# STM32H743 register map
File version: 2.4
CPU: CM7 r0p1, little endian, MPU, FPU, 4 interrupt priority bits
Registers are 32-bit, read-write, reset 0x0 unless marked. A register's access mark holds for its fields unless they carry their own. Offsets are from the block's base; [hi:lo] are bit positions; {n}, {i} and the like mark numbered series.

## DCMI — 数字摄像头接口
Base 0x48020000
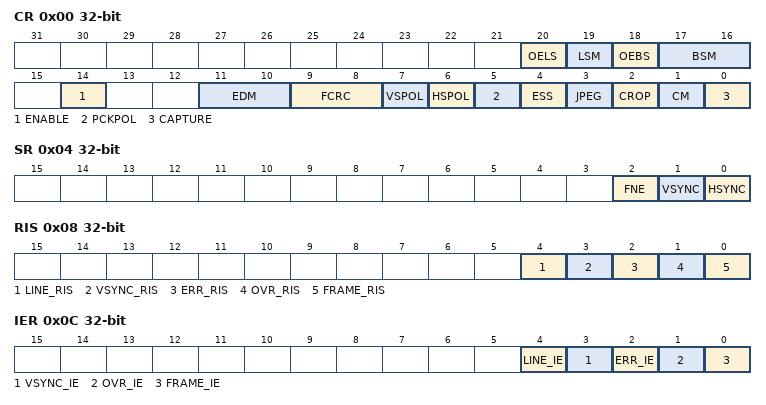
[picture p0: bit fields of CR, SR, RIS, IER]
0x00 CR — 控制寄存器 1
  [20] OELS — 奇/偶行选择（行选择起始）
  [19] LSM — 行选择模式
  [18] OEBS — 奇/偶字节选择（字节选择起始）
  [17:16] BSM — 字节选择模式
  [14] ENABLE — DCMI 使能
  [11:10] EDM — 扩展数据模式
  [9:8] FCRC — 帧捕获速率控制
  [7] VSPOL — 垂直同步极性
  [6] HSPOL — 水平同步极性
  [5] PCKPOL — 像素时钟极性
  [4] ESS — 内嵌同步选择
  [3] JPEG — JPEG 格式
  [2] CROP — 裁剪功能
  [1] CM — 捕获模式
  [0] CAPTURE — 捕获使能
0x04 SR ro — 状态寄存器
  [2] FNE — FIFO 非空
  [1] VSYNC
  [0] HSYNC
0x08 RIS ro — 原始中断状态寄存器
  [4] LINE_RIS — 行原始中断状态
  [3] VSYNC_RIS — VSYNC 原始中断状态
  [2] ERR_RIS — 同步错误原始中断状态
  [1] OVR_RIS — 溢出原始中断状态
  [0] FRAME_RIS — 捕获完成原始中断状态
0x0C IER — 中断使能寄存器
  [4] LINE_IE — 行中断使能
  [3] VSYNC_IE — VSYNC 中断使能
  [2] ERR_IE — 同步错误中断使能
  [1] OVR_IE — 溢出中断使能
  [0] FRAME_IE — 捕获完成中断使能
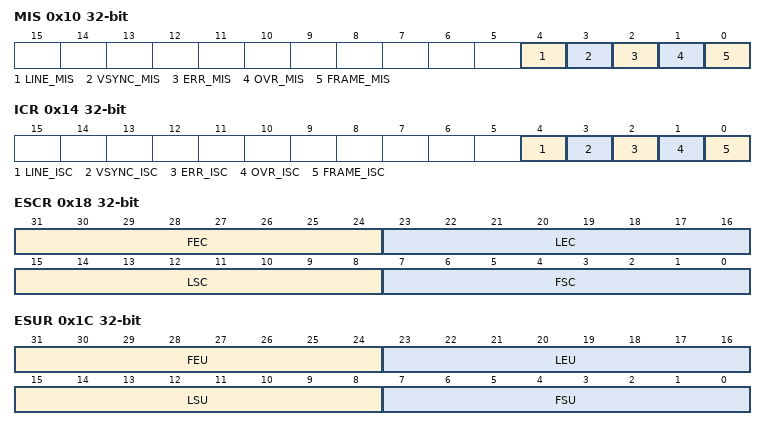
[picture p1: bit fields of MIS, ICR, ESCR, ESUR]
0x10 MIS ro — 已屏蔽中断状态寄存器
  [4] LINE_MIS — 行已屏蔽中断状态
  [3] VSYNC_MIS — VSYNC 已屏蔽中断状态
  [2] ERR_MIS — 同步错误已屏蔽中断状态
  [1] OVR_MIS — 溢出已屏蔽中断状态
  [0] FRAME_MIS — 捕获完成已屏蔽中断状态
0x14 ICR wo — 中断清除寄存器
  [4] LINE_ISC — 行中断状态清除
  [3] VSYNC_ISC — 垂直同步中断状态清除
  [2] ERR_ISC — 同步错误中断状态清除
  [1] OVR_ISC — 溢出中断状态清除
  [0] FRAME_ISC — 捕获完成中断状态清除
0x18 ESCR — 内嵌同步码寄存器
  [31:24] FEC — 帧结束分隔码
  [23:16] LEC — 行结束分隔码
  [15:8] LSC — 行起始分隔码
  [7:0] FSC — 帧起始分隔码
0x1C ESUR — 内嵌同步非屏蔽寄存器
  [31:24] FEU — 帧结束分隔符非屏蔽
  [23:16] LEU — 行结束分隔符非屏蔽
  [15:8] LSU — 行起始分隔符非屏蔽
  [7:0] FSU — 帧起始分隔符非屏蔽
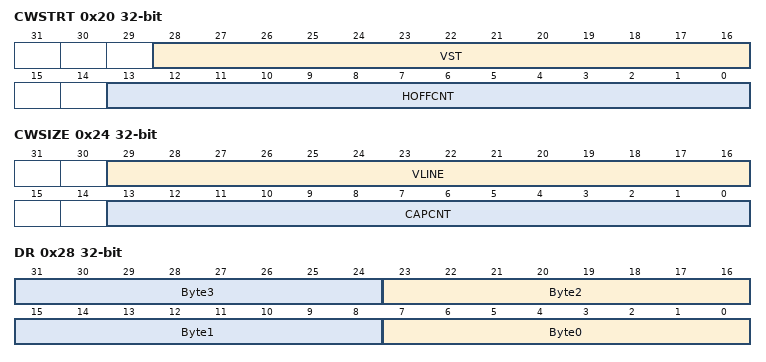
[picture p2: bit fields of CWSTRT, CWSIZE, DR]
0x20 CWSTRT — 裁剪窗口起始
  [28:16] VST — 垂直起始行计数
  [13:0] HOFFCNT — 水平偏移计数
0x24 CWSIZE — 裁剪窗口大小
  [29:16] VLINE — 垂直行数
  [13:0] CAPCNT — 捕获计数
0x28 DR ro — 数据寄存器
  [8n+7:8n] Byte{n} (n=0..3) — 数据字节 {n}

## OTG1_HS_PWRCLK — USB 1 OTG 高速接口
Base 0x40040E00
Same registers: OTG2_HS_PWRCLK 0x40080E00
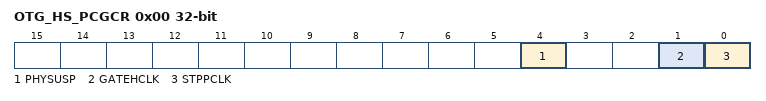
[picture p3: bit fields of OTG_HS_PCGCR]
0x00 OTG_HS_PCGCR — 功耗与时钟门控寄存器
  [4] PHYSUSP — PHY 已挂起
  [1] GATEHCLK — 门控 HCLK
  [0] STPPCLK — 停止 PHY 时钟

## Ethernet_DMA — 以太网：DMA 控制器
Base 0x40029000
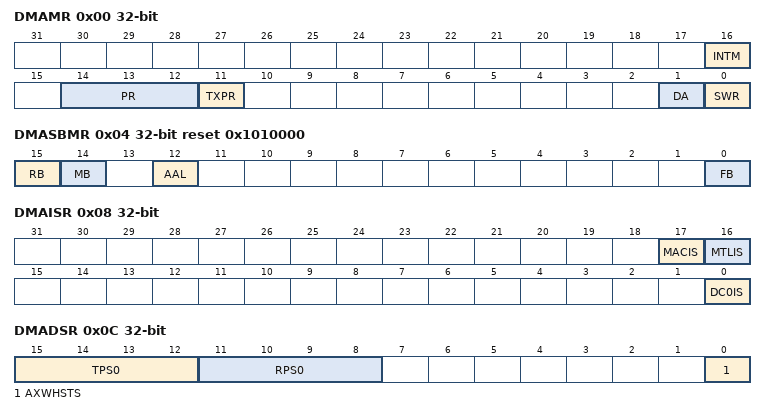
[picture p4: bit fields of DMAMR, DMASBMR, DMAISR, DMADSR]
0x00 DMAMR access per field — DMA 模式寄存器
  [16] INTM rw — 中断模式
  [14:12] PR ro — 优先级比例
  [11] TXPR ro — 发送优先级
  [1] DA ro — DMA 发送或接收仲裁方案
  [0] SWR rw — 软件复位
0x04 DMASBMR access per field reset 0x1010000 — 系统总线模式寄存器
  [15] RB ro — 重建 INCRx 突发
  [14] MB ro — 混合突发
  [12] AAL rw — 地址对齐节拍
  [0] FB rw — 固定突发长度
0x08 DMAISR ro — 中断状态寄存器
  [17] MACIS — MAC 中断状态
  [16] MTLIS — MTL 中断状态
  [0] DC0IS — DMA 通道中断状态
0x0C DMADSR ro — 调试状态寄存器
  [15:12] TPS0 — DMA 通道发送处理状态
  [11:8] RPS0 — DMA 通道接收处理状态
  [0] AXWHSTS — AHB 主写通道
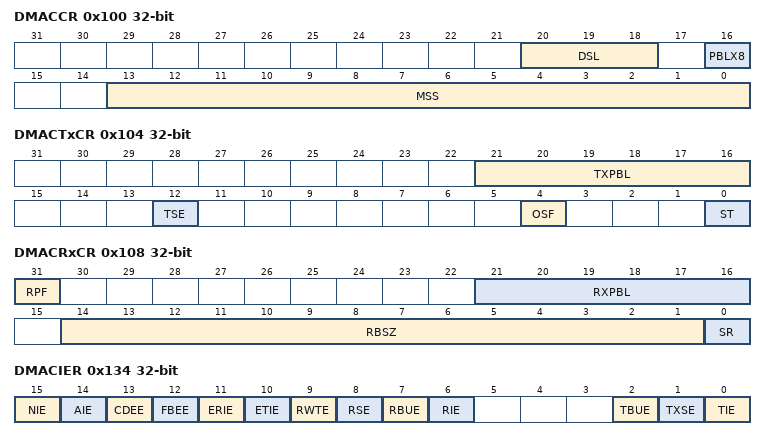
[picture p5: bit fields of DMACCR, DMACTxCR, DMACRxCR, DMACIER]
0x100 DMACCR — 通道控制寄存器
  [20:18] DSL — 描述符跳跃长度
  [16] PBLX8 — 8 倍 PBL 模式
  [13:0] MSS — 最大段大小
0x104 DMACTxCR — 通道发送控制寄存器
  [21:16] TXPBL — 发送可编程突发长度
  [12] TSE — TCP 分段使能
  [4] OSF — 第二包操作
  [0] ST — 启动或停止传输命令
0x108 DMACRxCR — 通道接收控制寄存器
  [31] RPF — DMA 接收通道数据包刷新
  [21:16] RXPBL — 接收可编程突发长度
  [14:1] RBSZ — 接收缓冲区大小
  [0] SR — 启动或停止接收命令
0x114 DMACTxDLAR — 通道发送描述符列表地址寄存器
  [31:2] TDESLA — 发送列表起始地址
0x11C DMACRxDLAR — 通道接收描述符列表地址寄存器
  [31:2] RDESLA — 接收列表起始地址
0x120 DMACTxDTPR — 通道发送描述符尾指针寄存器
  [31:2] TDT — 发送描述符尾指针
0x128 DMACRxDTPR — 通道接收描述符尾指针寄存器
  [31:2] RDT — 接收描述符尾指针
0x12C DMACTxRLR — 通道发送描述符环长度寄存器
  [9:0] TDRL — 发送描述符环长度
0x130 DMACRxRLR — 通道接收描述符环长度寄存器
  [9:0] RDRL — 接收描述符环长度
0x134 DMACIER — 通道中断使能寄存器
  [15] NIE — 正常中断汇总使能
  [14] AIE — 异常中断汇总使能
  [13] CDEE — 上下文描述符错误使能
  [12] FBEE — 致命总线错误使能
  [11] ERIE — 提前接收中断使能
  [10] ETIE — 提前发送中断使能
  [9] RWTE — 接收看门狗超时使能
  [8] RSE — 接收停止使能
  [7] RBUE — 接收缓冲区不可用使能
  [6] RIE — 接收中断使能
  [2] TBUE — 发送缓冲区不可用使能
  [1] TXSE — 发送停止使能
  [0] TIE — 发送中断使能
0x138 DMACRxIWTR — 通道接收中断看门狗定时器寄存器
  [7:0] RWT — 接收中断看门狗定时器计数值
0x144 DMACCATxDR ro — 通道当前应用发送描述符寄存器
  [31:0] CURTDESAPTR — 应用发送描述符地址指针
0x14C DMACCARxDR ro — 通道当前应用接收描述符寄存器
  [31:0] CURRDESAPTR — 应用接收描述符地址指针
0x154 DMACCATxBR ro — 通道当前应用发送缓冲区寄存器
  [31:0] CURTBUFAPTR — 应用发送缓冲区地址指针
0x15C DMACCARxBR ro — 通道当前应用接收缓冲区寄存器
  [31:0] CURRBUFAPTR — 应用接收缓冲区地址指针
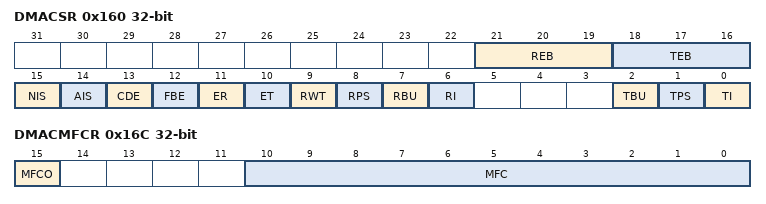
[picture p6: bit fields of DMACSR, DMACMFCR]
0x160 DMACSR access per field — 通道状态寄存器
  [21:19] REB ro — 接收 DMA 错误位
  [18:16] TEB ro — 发送 DMA 错误位
  [15] NIS rw — 正常中断汇总
  [14] AIS rw — 异常中断汇总
  [13] CDE rw — 上下文描述符错误
  [12] FBE rw — 致命总线错误
  [11] ER rw — 提前接收中断
  [10] ET rw — 提前发送中断
  [9] RWT rw — 接收看门狗超时
  [8] RPS rw — 接收处理已停止
  [7] RBU rw — 接收缓冲区不可用
  [6] RI rw — 接收中断
  [2] TBU rw — 发送缓冲区不可用
  [1] TPS rw — 发送处理已停止
  [0] TI rw — 发送中断
0x16C DMACMFCR ro — 通道丢帧计数寄存器
  [15] MFCO — MFC 计数器溢出状态
  [10:0] MFC — 丢弃数据包计数器
